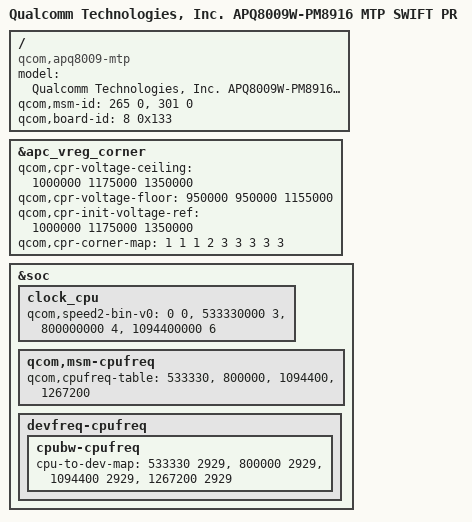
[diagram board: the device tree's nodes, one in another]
/*
 * Copyright (c) 2015-2016, The Linux Foundation. All rights reserved.
 *
 * This program is free software; you can redistribute it and/or modify
 * it under the terms of the GNU General Public License version 2 and
 * only version 2 as published by the Free Software Foundation.
 *
 * This program is distributed in the hope that it will be useful,
 * but WITHOUT ANY WARRANTY; without even the implied warranty of
 * MERCHANTABILITY or FITNESS FOR A PARTICULAR PURPOSE.  See the
 * GNU General Public License for more details.
 */

/dts-v1/;

#include "swift-pr_msm8909-mtp.dtsi"
#include "swift-pr_msm8909w-gpu.dtsi"
#include "swift-pr_msm8909-pm8916.dtsi"
#include "swift-pr_msm8909-pm8916-mtp.dtsi"
#include "swift-pr_msm8909w.dtsi"
#include "apq8009w-memory.dtsi"

/ {
	model = "Qualcomm Technologies, Inc. APQ8009W-PM8916 MTP SWIFT PR";
	compatible = "qcom,apq8009-mtp", "qcom,apq8009", "qcom,mtp";
	qcom,msm-id = <265 0>,
		      <301 0>;
	qcom,board-id= <8 0x133>;
};

&apc_vreg_corner {
	qcom,cpr-voltage-ceiling = <1000000 1175000 1350000>;
	qcom,cpr-voltage-floor = <950000 950000 1155000>;
	qcom,cpr-init-voltage-ref = <1000000 1175000 1350000>;
	qcom,cpr-corner-map = <1 1 1 2 3 3 3 3 3>;
};

&soc {
	clock_cpu {
		qcom,speed2-bin-v0 =
			<          0 0>,
			<  533330000 3>,
			<  800000000 4>,
			< 1094400000 6>;
	};

	qcom,msm-cpufreq {
		qcom,cpufreq-table =
			 <  533330 >,
			 <  800000 >,
			 < 1094400 >,
			 < 1267200 >;
	};

	devfreq-cpufreq {
		cpubw-cpufreq {
			cpu-to-dev-map =
				 <  533330  2929>,
				 <  800000  2929>,
				 < 1094400  2929>,
				 < 1267200  2929>;
		};
	};
};
